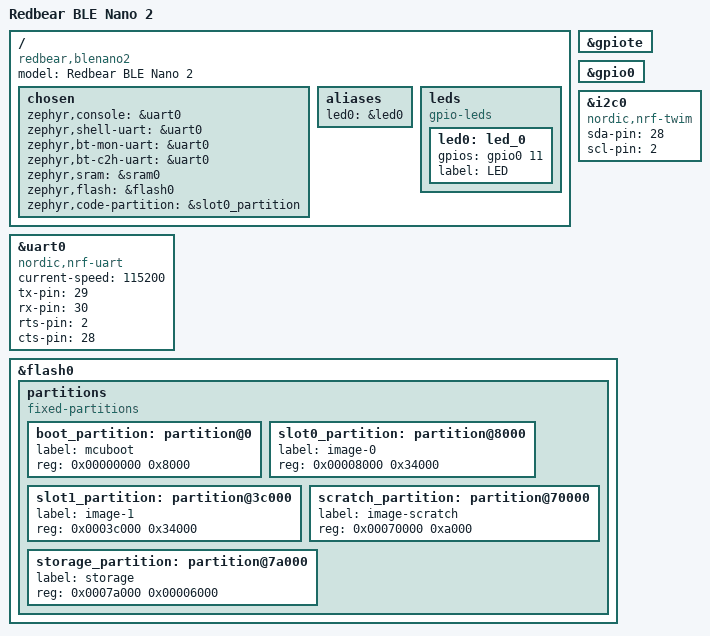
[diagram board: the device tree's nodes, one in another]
/*
 * Copyright (c) 2017 Linaro Limited
 *
 * SPDX-License-Identifier: Apache-2.0
 */

/dts-v1/;
#include <nordic/nrf52832_qfaa.dtsi>

/ {
	model = "Redbear BLE Nano 2";
	compatible = "redbear,blenano2";

	chosen {
		zephyr,console = &uart0;
		zephyr,shell-uart = &uart0;
		zephyr,bt-mon-uart = &uart0;
		zephyr,bt-c2h-uart = &uart0;
		zephyr,sram = &sram0;
		zephyr,flash = &flash0;
		zephyr,code-partition = &slot0_partition;
	};

	/* These aliases are provided for compatibility with samples */
	aliases {
		led0 = &led0;
	};

	leds {
		compatible = "gpio-leds";
		led0: led_0 {
			gpios = <&gpio0 11 0>;
			label = "LED";
		};
	};
};

&gpiote {
	status = "okay";
};

&gpio0 {
	status = "okay";
};

&uart0 {
	compatible = "nordic,nrf-uart";
	current-speed = <115200>;
	status = "okay";
	tx-pin = <29>;
	rx-pin = <30>;
	rts-pin = <2>;
	cts-pin = <28>;
};

&i2c0 {
	compatible = "nordic,nrf-twim";
	status = "okay";
	sda-pin = <28>;
	scl-pin = <2>;
};

&flash0 {

	partitions {
		compatible = "fixed-partitions";
		#address-cells = <1>;
		#size-cells = <1>;

		boot_partition: partition@0 {
			label = "mcuboot";
			reg = <0x00000000 0x8000>;
		};
		slot0_partition: partition@8000 {
			label = "image-0";
			reg = <0x00008000 0x34000>;
		};
		slot1_partition: partition@3c000 {
			label = "image-1";
			reg = <0x0003c000 0x34000>;
		};
		scratch_partition: partition@70000 {
			label = "image-scratch";
			reg = <0x00070000 0xa000>;
		};

		/*
		 * The flash starting at 0x0007a000 and ending at
		 * 0x0007ffff (sectors 122-127) is reserved for use
		 * by the application.
		 * Storage partition will be used by FCB/LittleFS/NVS
		 * if enabled.
		 */
		storage_partition: partition@7a000 {
			label = "storage";
			reg = <0x0007a000 0x00006000>;
		};
	};
};
